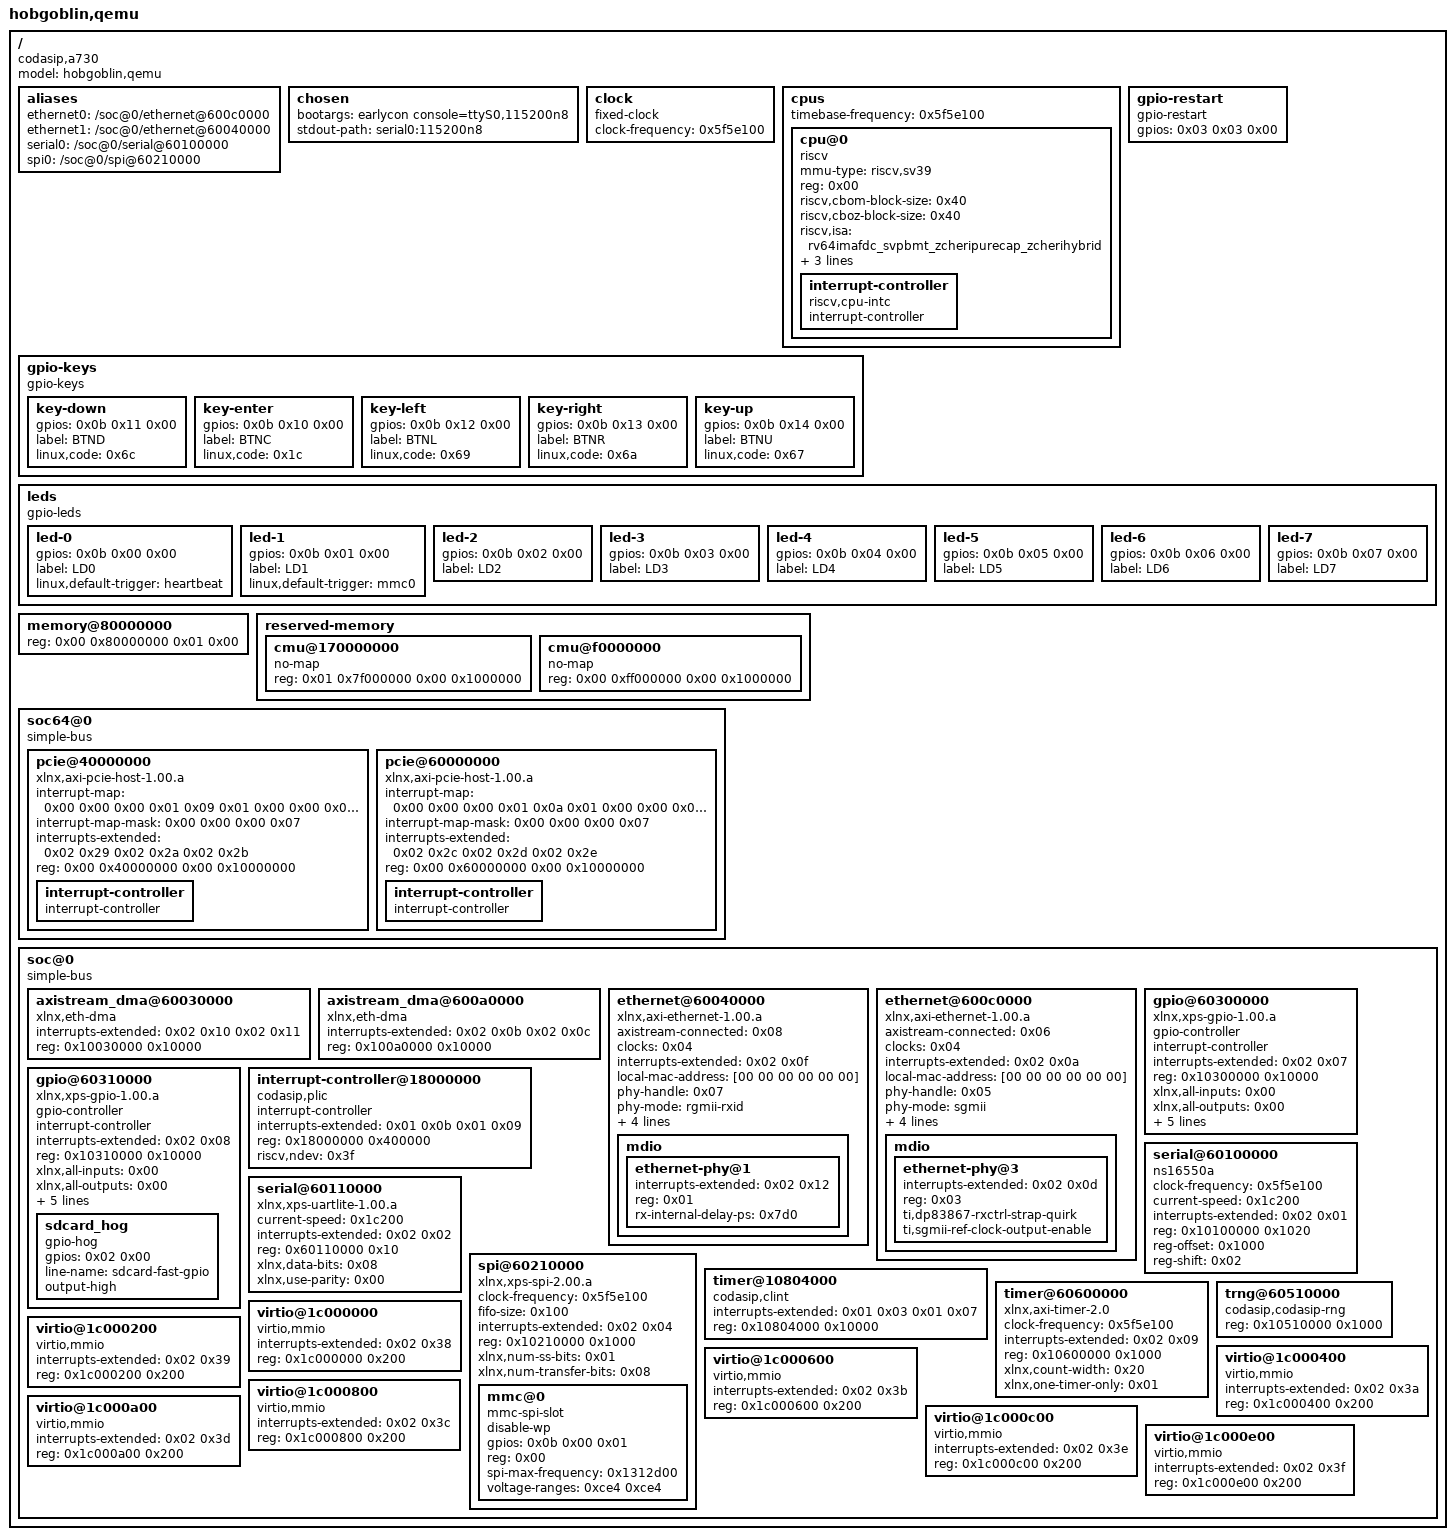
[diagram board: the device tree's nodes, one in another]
/dts-v1/;

/ {
	#address-cells = <0x02>;
	#size-cells = <0x02>;
	compatible = "codasip,a730";
	model = "hobgoblin,qemu";

	aliases {
		ethernet0 = "/soc@0/ethernet@600c0000";
		ethernet1 = "/soc@0/ethernet@60040000";
		serial0 = "/soc@0/serial@60100000";
		spi0 = "/soc@0/spi@60210000";
	};

	chosen {
		bootargs = "earlycon console=ttyS0,115200n8";
		stdout-path = "serial0:115200n8";
	};

	clock {
		#clock-cells = <0x00>;
		clock-frequency = <0x5f5e100>;
		compatible = "fixed-clock";
		phandle = <0x04>;
	};

	cpus {
		#address-cells = <0x01>;
		#size-cells = <0x00>;
		timebase-frequency = <0x5f5e100>;

		cpu@0 {
			compatible = "riscv";
			device_type = "cpu";
			mmu-type = "riscv,sv39";
			reg = <0x00>;
			riscv,cbom-block-size = <0x40>;
			riscv,cboz-block-size = <0x40>;
			riscv,isa = "rv64imafdc_svpbmt_zcheripurecap_zcherihybrid";
			riscv,isa-base = "rv64i";
			riscv,isa-extensions = "i\0m\0a\0f\0d\0c\0svpbmt\0zcheripurecap\0zcherihybrid";
			status = "okay";

			interrupt-controller {
				#address-cells = <0x00>;
				#interrupt-cells = <0x01>;
				compatible = "riscv,cpu-intc";
				interrupt-controller;
				phandle = <0x01>;
				status = "okay";
			};
		};
	};

	gpio-keys {
		compatible = "gpio-keys";

		key-down {
			gpios = <0x0b 0x11 0x00>;
			label = "BTND";
			linux,code = <0x6c>;
		};

		key-enter {
			gpios = <0x0b 0x10 0x00>;
			label = "BTNC";
			linux,code = <0x1c>;
		};

		key-left {
			gpios = <0x0b 0x12 0x00>;
			label = "BTNL";
			linux,code = <0x69>;
		};

		key-right {
			gpios = <0x0b 0x13 0x00>;
			label = "BTNR";
			linux,code = <0x6a>;
		};

		key-up {
			gpios = <0x0b 0x14 0x00>;
			label = "BTNU";
			linux,code = <0x67>;
		};
	};

	gpio-restart {
		compatible = "gpio-restart";
		gpios = <0x03 0x03 0x00>;
	};

	leds {
		compatible = "gpio-leds";

		led-0 {
			gpios = <0x0b 0x00 0x00>;
			label = "LD0";
			linux,default-trigger = "heartbeat";
		};

		led-1 {
			gpios = <0x0b 0x01 0x00>;
			label = "LD1";
			linux,default-trigger = "mmc0";
		};

		led-2 {
			gpios = <0x0b 0x02 0x00>;
			label = "LD2";
		};

		led-3 {
			gpios = <0x0b 0x03 0x00>;
			label = "LD3";
		};

		led-4 {
			gpios = <0x0b 0x04 0x00>;
			label = "LD4";
		};

		led-5 {
			gpios = <0x0b 0x05 0x00>;
			label = "LD5";
		};

		led-6 {
			gpios = <0x0b 0x06 0x00>;
			label = "LD6";
		};

		led-7 {
			gpios = <0x0b 0x07 0x00>;
			label = "LD7";
		};
	};

	memory@80000000 {
		device_type = "memory";
		reg = <0x00 0x80000000 0x01 0x00>;
	};

	reserved-memory {
		#address-cells = <0x02>;
		#size-cells = <0x02>;
		ranges;

		cmu@170000000 {
			no-map;
			reg = <0x01 0x7f000000 0x00 0x1000000>;
		};

		cmu@f0000000 {
			no-map;
			reg = <0x00 0xff000000 0x00 0x1000000>;
		};
	};

	soc64@0 {
		#address-cells = <0x02>;
		#size-cells = <0x02>;
		compatible = "simple-bus";
		ranges = <0x00 0x00 0x00 0x00 0x40 0x00>;

		pcie@40000000 {
			#address-cells = <0x03>;
			#interrupt-cells = <0x01>;
			#size-cells = <0x02>;
			compatible = "xlnx,axi-pcie-host-1.00.a";
			device_type = "pci";
			interrupt-map = <0x00 0x00 0x00 0x01 0x09 0x01 0x00 0x00 0x00 0x02 0x09 0x02 0x00 0x00 0x00 0x03 0x09 0x03 0x00 0x00 0x00 0x04 0x09 0x04>;
			interrupt-map-mask = <0x00 0x00 0x00 0x07>;
			interrupts-extended = <0x02 0x29 0x02 0x2a 0x02 0x2b>;
			ranges = <0x2000000 0x00 0x50000000 0x00 0x50000000 0x00 0x10000000 0x43000000 0x10 0x00 0x10 0x00 0x01 0x00>;
			reg = <0x00 0x40000000 0x00 0x10000000>;

			interrupt-controller {
				#address-cells = <0x00>;
				#interrupt-cells = <0x01>;
				interrupt-controller;
				phandle = <0x09>;
			};
		};

		pcie@60000000 {
			#address-cells = <0x03>;
			#interrupt-cells = <0x01>;
			#size-cells = <0x02>;
			compatible = "xlnx,axi-pcie-host-1.00.a";
			device_type = "pci";
			interrupt-map = <0x00 0x00 0x00 0x01 0x0a 0x01 0x00 0x00 0x00 0x02 0x0a 0x02 0x00 0x00 0x00 0x03 0x0a 0x03 0x00 0x00 0x00 0x04 0x0a 0x04>;
			interrupt-map-mask = <0x00 0x00 0x00 0x07>;
			interrupts-extended = <0x02 0x2c 0x02 0x2d 0x02 0x2e>;
			ranges = <0x2000000 0x00 0x70000000 0x00 0x70000000 0x00 0x10000000 0x43000000 0x11 0x00 0x11 0x00 0x01 0x00>;
			reg = <0x00 0x60000000 0x00 0x10000000>;

			interrupt-controller {
				#address-cells = <0x00>;
				#interrupt-cells = <0x01>;
				interrupt-controller;
				phandle = <0x0a>;
			};
		};
	};

	soc@0 {
		#address-cells = <0x01>;
		#size-cells = <0x01>;
		compatible = "simple-bus";
		ranges = <0x00 0x00 0x00 0x80000000>;

		axistream_dma@60030000 {
			compatible = "xlnx,eth-dma";
			interrupts-extended = <0x02 0x10 0x02 0x11>;
			phandle = <0x08>;
			reg = <0x10030000 0x10000>;
		};

		axistream_dma@600a0000 {
			compatible = "xlnx,eth-dma";
			interrupts-extended = <0x02 0x0b 0x02 0x0c>;
			phandle = <0x06>;
			reg = <0x100a0000 0x10000>;
		};

		ethernet@60040000 {
			axistream-connected = <0x08>;
			clock-names = "s_axi_lite_clk";
			clocks = <0x04>;
			compatible = "xlnx,axi-ethernet-1.00.a";
			interrupts-extended = <0x02 0x0f>;
			local-mac-address = [00 00 00 00 00 00];
			phy-handle = <0x07>;
			phy-mode = "rgmii-rxid";
			reg = <0x10040000 0x40000>;
			xlnx,rxcsum = <0x02>;
			xlnx,rxmem = <0x4000>;
			xlnx,txcsum = <0x02>;

			mdio {
				#address-cells = <0x01>;
				#size-cells = <0x00>;

				ethernet-phy@1 {
					device_type = "ethernet-phy";
					interrupts-extended = <0x02 0x12>;
					phandle = <0x07>;
					reg = <0x01>;
					rx-internal-delay-ps = <0x7d0>;
				};
			};
		};

		ethernet@600c0000 {
			axistream-connected = <0x06>;
			clock-names = "s_axi_lite_clk";
			clocks = <0x04>;
			compatible = "xlnx,axi-ethernet-1.00.a";
			interrupts-extended = <0x02 0x0a>;
			local-mac-address = [00 00 00 00 00 00];
			phy-handle = <0x05>;
			phy-mode = "sgmii";
			reg = <0x100c0000 0x40000>;
			xlnx,rxcsum = <0x02>;
			xlnx,rxmem = <0x4000>;
			xlnx,txcsum = <0x02>;

			mdio {
				#address-cells = <0x01>;
				#size-cells = <0x00>;

				ethernet-phy@3 {
					device_type = "ethernet-phy";
					interrupts-extended = <0x02 0x0d>;
					phandle = <0x05>;
					reg = <0x03>;
					ti,dp83867-rxctrl-strap-quirk;
					ti,sgmii-ref-clock-output-enable;
				};
			};
		};

		gpio@60300000 {
			#address-cells = <0x00>;
			#gpio-cells = <0x02>;
			#interrupt-cells = <0x02>;
			compatible = "xlnx,xps-gpio-1.00.a";
			gpio-controller;
			interrupt-controller;
			interrupts-extended = <0x02 0x07>;
			phandle = <0x0b>;
			reg = <0x10300000 0x10000>;
			xlnx,all-inputs = <0x00>;
			xlnx,all-outputs = <0x00>;
			xlnx,dout-default = <0x00>;
			xlnx,gpio-width = <0x20>;
			xlnx,interrupt-present = <0x01>;
			xlnx,is-dual = <0x00>;
			xlnx,tri-default = <0xfe>;
		};

		gpio@60310000 {
			#address-cells = <0x00>;
			#gpio-cells = <0x02>;
			#interrupt-cells = <0x02>;
			compatible = "xlnx,xps-gpio-1.00.a";
			gpio-controller;
			interrupt-controller;
			interrupts-extended = <0x02 0x08>;
			phandle = <0x03>;
			reg = <0x10310000 0x10000>;
			xlnx,all-inputs = <0x00>;
			xlnx,all-outputs = <0x00>;
			xlnx,dout-default = <0x00>;
			xlnx,gpio-width = <0x20>;
			xlnx,interrupt-present = <0x01>;
			xlnx,is-dual = <0x00>;
			xlnx,tri-default = <0x01>;

			sdcard_hog {
				gpio-hog;
				gpios = <0x02 0x00>;
				line-name = "sdcard-fast-gpio";
				output-high;
			};
		};

		interrupt-controller@18000000 {
			#address-cells = <0x00>;
			#interrupt-cells = <0x01>;
			compatible = "codasip,plic\0sifive,plic-1.0.0\0riscv,plic0";
			interrupt-controller;
			interrupts-extended = <0x01 0x0b 0x01 0x09>;
			phandle = <0x02>;
			reg = <0x18000000 0x400000>;
			riscv,ndev = <0x3f>;
		};

		serial@60100000 {
			clock-frequency = <0x5f5e100>;
			compatible = "ns16550a";
			current-speed = <0x1c200>;
			interrupts-extended = <0x02 0x01>;
			reg = <0x10100000 0x1020>;
			reg-offset = <0x1000>;
			reg-shift = <0x02>;
		};

		serial@60110000 {
			compatible = "xlnx,xps-uartlite-1.00.a";
			current-speed = <0x1c200>;
			interrupts-extended = <0x02 0x02>;
			reg = <0x60110000 0x10>;
			xlnx,data-bits = <0x08>;
			xlnx,use-parity = <0x00>;
		};

		spi@60210000 {
			#address-cells = <0x01>;
			#size-cells = <0x00>;
			clock-frequency = <0x5f5e100>;
			compatible = "xlnx,xps-spi-2.00.a";
			fifo-size = <0x100>;
			interrupts-extended = <0x02 0x04>;
			reg = <0x10210000 0x1000>;
			xlnx,num-ss-bits = <0x01>;
			xlnx,num-transfer-bits = <0x08>;

			mmc@0 {
				compatible = "mmc-spi-slot";
				disable-wp;
				gpios = <0x0b 0x00 0x01>;
				reg = <0x00>;
				spi-max-frequency = <0x1312d00>;
				voltage-ranges = <0xce4 0xce4>;
			};
		};

		timer@10804000 {
			compatible = "codasip,clint\0sifive,clint0\0riscv,clint0";
			interrupts-extended = <0x01 0x03 0x01 0x07>;
			reg = <0x10804000 0x10000>;
		};

		timer@60600000 {
			clock-frequency = <0x5f5e100>;
			compatible = "xlnx,axi-timer-2.0\0xlnx,xps-timer-1.00.a";
			interrupts-extended = <0x02 0x09>;
			reg = <0x10600000 0x1000>;
			xlnx,count-width = <0x20>;
			xlnx,one-timer-only = <0x01>;
		};

		trng@60510000 {
			compatible = "codasip,codasip-rng";
			reg = <0x10510000 0x1000>;
		};

		virtio@1c000000 {
			compatible = "virtio,mmio";
			interrupts-extended = <0x02 0x38>;
			reg = <0x1c000000 0x200>;
		};

		virtio@1c000200 {
			compatible = "virtio,mmio";
			interrupts-extended = <0x02 0x39>;
			reg = <0x1c000200 0x200>;
		};

		virtio@1c000400 {
			compatible = "virtio,mmio";
			interrupts-extended = <0x02 0x3a>;
			reg = <0x1c000400 0x200>;
		};

		virtio@1c000600 {
			compatible = "virtio,mmio";
			interrupts-extended = <0x02 0x3b>;
			reg = <0x1c000600 0x200>;
		};

		virtio@1c000800 {
			compatible = "virtio,mmio";
			interrupts-extended = <0x02 0x3c>;
			reg = <0x1c000800 0x200>;
		};

		virtio@1c000a00 {
			compatible = "virtio,mmio";
			interrupts-extended = <0x02 0x3d>;
			reg = <0x1c000a00 0x200>;
		};

		virtio@1c000c00 {
			compatible = "virtio,mmio";
			interrupts-extended = <0x02 0x3e>;
			reg = <0x1c000c00 0x200>;
		};

		virtio@1c000e00 {
			compatible = "virtio,mmio";
			interrupts-extended = <0x02 0x3f>;
			reg = <0x1c000e00 0x200>;
		};
	};
};
